# LM3S1P51 register map
File version: 7944
Registers are 32-bit, read-write, no defined reset value unless marked. A register's access mark holds for its fields unless they carry their own. Offsets are from the block's base; [hi:lo] are bit positions.

## TIMER0 — Register map for TIMER0 peripheral
Base 0x40030000; register names take the prefix TIMER0
Same registers: TIMER1 0x40031000 (register names take the prefix TIMER1), TIMER2 0x40032000 (register names take the prefix TIMER2), TIMER3 0x40033000 (register names take the prefix TIMER3)
0x00 CFG — GPTM Configuration
  [2:0] TIMER_CFG
    0=TIMER_CFG_32_BIT_TIMER (32-bit timer configuration); 1=TIMER_CFG_32_BIT_RTC (32-bit real-time clock (RTC) counter configuration); 4=TIMER_CFG_16_BIT (16-bit timer configuration. The function is controlled by bits 1:0 of GPTMTAMR and GPTMTBMR)
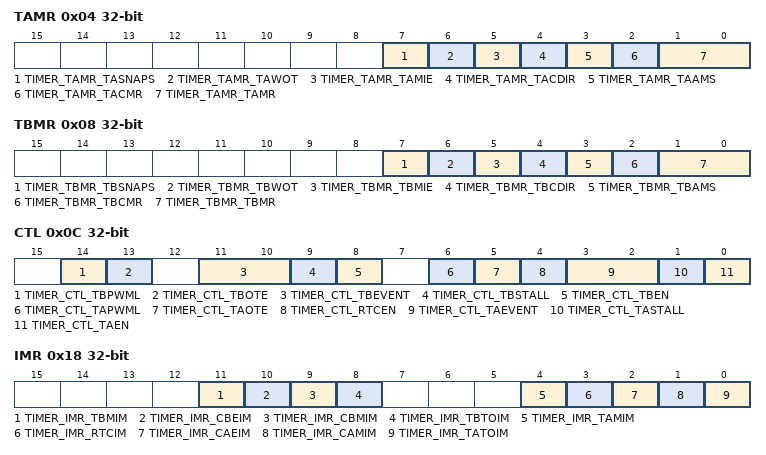
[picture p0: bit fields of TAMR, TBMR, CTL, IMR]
0x04 TAMR — GPTM Timer A Mode
  [7] TIMER_TAMR_TASNAPS — GPTM Timer A Snap-Shot Mode
  [6] TIMER_TAMR_TAWOT — GPTM Timer A Wait-on-Trigger
  [5] TIMER_TAMR_TAMIE — GPTM Timer A Match Interrupt Enable
  [4] TIMER_TAMR_TACDIR — GPTM Timer A Count Direction
  [3] TIMER_TAMR_TAAMS — GPTM Timer A Alternate Mode Select
  [2] TIMER_TAMR_TACMR — GPTM Timer A Capture Mode
  [1:0] TIMER_TAMR_TAMR — GPTM Timer A Mode
    1=TIMER_TAMR_TAMR_1_SHOT (One-Shot Timer mode); 2=TIMER_TAMR_TAMR_PERIOD (Periodic Timer mode); 3=TIMER_TAMR_TAMR_CAP (Capture mode)
0x08 TBMR — GPTM Timer B Mode
  [7] TIMER_TBMR_TBSNAPS — GPTM Timer B Snap-Shot Mode
  [6] TIMER_TBMR_TBWOT — GPTM Timer B Wait-on-Trigger
  [5] TIMER_TBMR_TBMIE — GPTM Timer B Match Interrupt Enable
  [4] TIMER_TBMR_TBCDIR — GPTM Timer B Count Direction
  [3] TIMER_TBMR_TBAMS — GPTM Timer B Alternate Mode Select
  [2] TIMER_TBMR_TBCMR — GPTM Timer B Capture Mode
  [1:0] TIMER_TBMR_TBMR — GPTM Timer B Mode
    1=TIMER_TBMR_TBMR_1_SHOT (One-Shot Timer mode); 2=TIMER_TBMR_TBMR_PERIOD (Periodic Timer mode); 3=TIMER_TBMR_TBMR_CAP (Capture mode)
0x0C CTL — GPTM Control
  [14] TIMER_CTL_TBPWML — GPTM Timer B PWM Output Level
  [13] TIMER_CTL_TBOTE — GPTM Timer B Output Trigger Enable
  [11:10] TIMER_CTL_TBEVENT — GPTM Timer B Event Mode
    0=TIMER_CTL_TBEVENT_POS (Positive edge); 1=TIMER_CTL_TBEVENT_NEG (Negative edge); 3=TIMER_CTL_TBEVENT_BOTH (Both edges)
  [9] TIMER_CTL_TBSTALL — GPTM Timer B Stall Enable
  [8] TIMER_CTL_TBEN — GPTM Timer B Enable
  [6] TIMER_CTL_TAPWML — GPTM Timer A PWM Output Level
  [5] TIMER_CTL_TAOTE — GPTM Timer A Output Trigger Enable
  [4] TIMER_CTL_RTCEN — GPTM RTC Enable
  [3:2] TIMER_CTL_TAEVENT — GPTM Timer A Event Mode
    0=TIMER_CTL_TAEVENT_POS (Positive edge); 1=TIMER_CTL_TAEVENT_NEG (Negative edge); 3=TIMER_CTL_TAEVENT_BOTH (Both edges)
  [1] TIMER_CTL_TASTALL — GPTM Timer A Stall Enable
  [0] TIMER_CTL_TAEN — GPTM Timer A Enable
0x18 IMR — GPTM Interrupt Mask
  [11] TIMER_IMR_TBMIM — GPTM Timer B Mode Match Interrupt Mask
  [10] TIMER_IMR_CBEIM — GPTM Capture B Event Interrupt Mask
  [9] TIMER_IMR_CBMIM — GPTM Capture B Match Interrupt Mask
  [8] TIMER_IMR_TBTOIM — GPTM Timer B Time-Out Interrupt Mask
  [4] TIMER_IMR_TAMIM — GPTM Timer A Mode Match Interrupt Mask
  [3] TIMER_IMR_RTCIM — GPTM RTC Interrupt Mask
  [2] TIMER_IMR_CAEIM — GPTM Capture A Event Interrupt Mask
  [1] TIMER_IMR_CAMIM — GPTM Capture A Match Interrupt Mask
  [0] TIMER_IMR_TATOIM — GPTM Timer A Time-Out Interrupt Mask
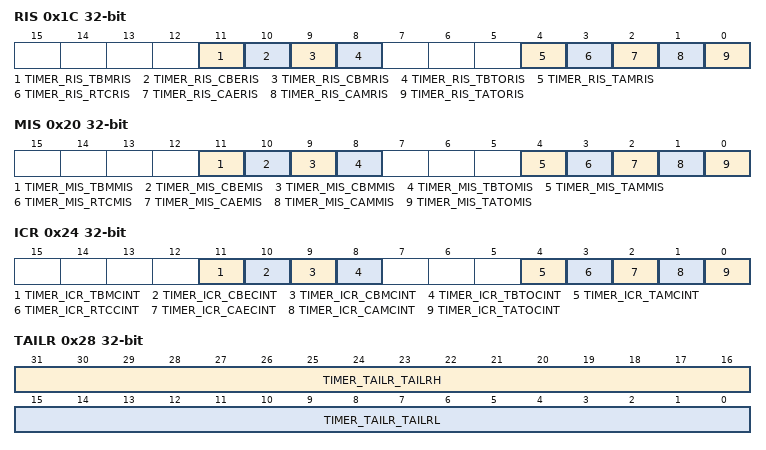
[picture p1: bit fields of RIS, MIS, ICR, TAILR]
0x1C RIS — GPTM Raw Interrupt Status
  [11] TIMER_RIS_TBMRIS — GPTM Timer B Mode Match Raw Interrupt
  [10] TIMER_RIS_CBERIS — GPTM Capture B Event Raw Interrupt
  [9] TIMER_RIS_CBMRIS — GPTM Capture B Match Raw Interrupt
  [8] TIMER_RIS_TBTORIS — GPTM Timer B Time-Out Raw Interrupt
  [4] TIMER_RIS_TAMRIS — GPTM Timer A Mode Match Raw Interrupt
  [3] TIMER_RIS_RTCRIS — GPTM RTC Raw Interrupt
  [2] TIMER_RIS_CAERIS — GPTM Capture A Event Raw Interrupt
  [1] TIMER_RIS_CAMRIS — GPTM Capture A Match Raw Interrupt
  [0] TIMER_RIS_TATORIS — GPTM Timer A Time-Out Raw Interrupt
0x20 MIS — GPTM Masked Interrupt Status
  [11] TIMER_MIS_TBMMIS — GPTM Timer B Mode Match Masked Interrupt
  [10] TIMER_MIS_CBEMIS — GPTM Capture B Event Masked Interrupt
  [9] TIMER_MIS_CBMMIS — GPTM Capture B Match Masked Interrupt
  [8] TIMER_MIS_TBTOMIS — GPTM Timer B Time-Out Masked Interrupt
  [4] TIMER_MIS_TAMMIS — GPTM Timer A Mode Match Masked Interrupt
  [3] TIMER_MIS_RTCMIS — GPTM RTC Masked Interrupt
  [2] TIMER_MIS_CAEMIS — GPTM Capture A Event Masked Interrupt
  [1] TIMER_MIS_CAMMIS — GPTM Capture A Match Masked Interrupt
  [0] TIMER_MIS_TATOMIS — GPTM Timer A Time-Out Masked Interrupt
0x24 ICR wo — GPTM Interrupt Clear
  [11] TIMER_ICR_TBMCINT — GPTM Timer B Mode Match Interrupt Clear
  [10] TIMER_ICR_CBECINT — GPTM Capture B Event Interrupt Clear
  [9] TIMER_ICR_CBMCINT — GPTM Capture B Match Interrupt Clear
  [8] TIMER_ICR_TBTOCINT — GPTM Timer B Time-Out Interrupt Clear
  [4] TIMER_ICR_TAMCINT — GPTM Timer A Mode Match Interrupt Clear
  [3] TIMER_ICR_RTCCINT — GPTM RTC Interrupt Clear
  [2] TIMER_ICR_CAECINT — GPTM Capture A Event Interrupt Clear
  [1] TIMER_ICR_CAMCINT — GPTM Capture A Match Interrupt Clear
  [0] TIMER_ICR_TATOCINT — GPTM Timer A Time-Out Raw Interrupt
0x28 TAILR — GPTM Timer A Interval Load
  [31:16] TIMER_TAILR_TAILRH — GPTM Timer A Interval Load Register High
  [15:0] TIMER_TAILR_TAILRL — GPTM Timer A Interval Load Register Low
0x2C TBILR — GPTM Timer B Interval Load
  [15:0] TIMER_TBILR_TBILRL — GPTM Timer B Interval Load Register
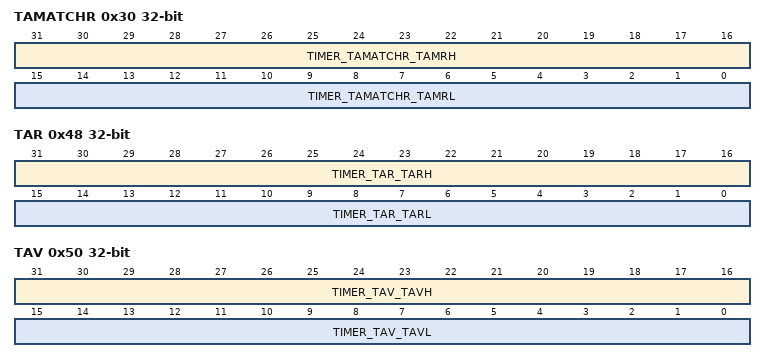
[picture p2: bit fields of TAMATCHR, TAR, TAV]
0x30 TAMATCHR — GPTM Timer A Match
  [31:16] TIMER_TAMATCHR_TAMRH — GPTM Timer A Match Register High
  [15:0] TIMER_TAMATCHR_TAMRL — GPTM Timer A Match Register Low
0x34 TBMATCHR — GPTM Timer B Match
  [15:0] TIMER_TBMATCHR_TBMRL — GPTM Timer B Match Register Low
0x38 TAPR — GPTM Timer A Prescale
  [7:0] TIMER_TAPR_TAPSR
0x3C TBPR — GPTM Timer B Prescale
  [7:0] TIMER_TBPR_TBPSR
0x40 TAPMR — GPTM TimerA Prescale Match
  [7:0] TIMER_TAPMR_TAPSMR
0x44 TBPMR — GPTM TimerB Prescale Match
  [7:0] TIMER_TBPMR_TBPSMR
0x48 TAR — GPTM Timer A
  [31:16] TIMER_TAR_TARH — GPTM Timer A Register High
  [15:0] TIMER_TAR_TARL — GPTM Timer A Register Low
0x4C TBR — GPTM Timer B
  [23:0] TIMER_TBR_TBRL
0x50 TAV — GPTM Timer A Value
  [31:16] TIMER_TAV_TAVH — GPTM Timer A Value High
  [15:0] TIMER_TAV_TAVL — GPTM Timer A Register Low
0x54 TBV — GPTM Timer B Value
  [15:0] TIMER_TBV_TBVL — GPTM Timer B Register
